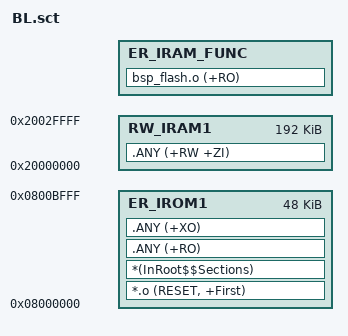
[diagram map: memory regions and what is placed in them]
; *************************************************************
; *** Scatter-Loading Description File generated by uVision ***
; *************************************************************

LR_IROM1 0x08000000 0x0000C000 {    ; 48KB BL 空间（对齐 16KB，正确）
  ER_IROM1 0x08000000 0x0000C000 {
   *.o (RESET, +First)
   *(InRoot$$Sections)
   .ANY (+RO)
   .ANY (+XO)
  }
  RW_IRAM1 0x20000000 0x00030000 { .ANY (+RW +ZI) }  ; STM32F407 192KB RAM
  ER_IRAM_FUNC +0 {                         
   bsp_flash.o (+RO)                         ; Flash 代码放 RAM 执行（正确）
  }
}

